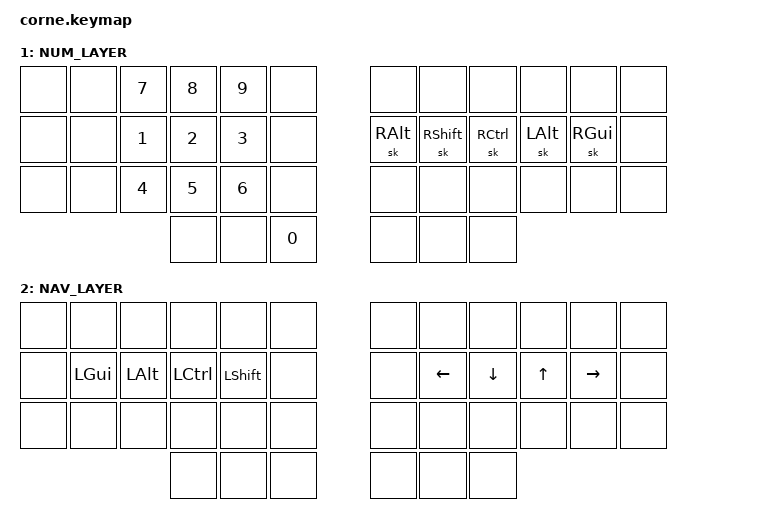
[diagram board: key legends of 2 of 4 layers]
/*
 * Copyright (c) 2020 The ZMK Contributors
 *
 * SPDX-License-Identifier: MIT
 */

#include <behaviors.dtsi>
#include <dt-bindings/zmk/keys.h>
#include <dt-bindings/zmk/bt.h>
#include <dt-bindings/zmk/outputs.h>

#include "wrappers.h"
#include "german.dtsi"

#define BASE_LAYER 0
#define NUM_LAYER 1
#define NAV_LAYER 2
#define BLE_LAYER 3

/ {

    behaviors {
        hm: homerow_mods {
            compatible = "zmk,behavior-hold-tap";
            label = "homerow mods";
            #binding-cells = <2>;
            tapping_term_ms = <110>;
            flavor = "tap-preferred";
            bindings = <&kp>, <&kp>;
        };

        mtl: mtl {
            compatible = "zmk,behavior-hold-tap";
            label = "Mod Tap Left";
            #binding-cells = <2>;
            flavor = "tap-preferred";
            tapping-term-ms = <333>;// <---[[produces mod if held longer than tapping-term-ms]]
            quick-tap-ms = <100>;
            bindings = <&kp>, <&kp>;
            hold-trigger-key-positions = <6 7 8 9 10 18 19 20 21 22 30 31 32 33 34 39 40 41>;    // <---[[right-hand keys]]
        };

        mtr: mtr {
            compatible = "zmk,behavior-hold-tap";
            label = "Mod Tap Right";
            #binding-cells = <2>;
            flavor = "tap-preferred";
            tapping-term-ms = <333>;// <---[[produces mod if held longer than tapping-term-ms]]
            quick-tap-ms = <100>;
            bindings = <&kp>, <&kp>;
            hold-trigger-key-positions = <1 2 3 4 5 13 14 15 16 17 25 26 27 28 29>;    // <---[[left-hand keys]]
        };
    };

 /* LEFT HAND SIDE POSITIONS
 *    ┌────┬────┬────┬────┬────┐
 * 00 │ 01 │ 02 │ 03 │ 04 │ 05 │ L
 *    ├────┼────┼────┼────┼────┤ E
 * 12 │ 13 │ 14 │ 15 │ 16 │ 17 │ F
 *    ├────┼────┼────┼────┼────┤ T
 * 24 │ 25 │ 26 │ 27 │ 28 │ 29 │
 *    └────┴────┴────┴────┴────┘
 */
    combos {
        compatible = "zmk,combos";

      // "<"
      combo_LESS_THAN {
            timeout-ms = <50>;
            key-positions = <1 2>;
            bindings = <&kp deLESS_THAN>;
        };

      // "("
      combo_LEFT_PARENTHESIS {
            timeout-ms = <50>;
            key-positions = <2 3>;
            bindings = <&kp deLEFT_PARENTHESIS>;
        };

      // "{"
      combo_LEFT_BRACE {
            timeout-ms = <50>;
            key-positions = <3 4>;
            bindings = <&kp deLEFT_BRACE>;
        };

      // "["
      combo_LEFT_BRACKET { // "["
            timeout-ms = <50>;
            key-positions = <4 5>;
            bindings = <&kp deLEFT_BRACKET>;
        };

      // "ESC"
      combo_esc {
            timeout-ms = <50>;
            key-positions = <15 16>;
            bindings = <&kp ESC>;
        };

      // "TAB"
      combo_tab {
            timeout-ms = <50>;
            key-positions = <14 15>;
            bindings = <&kp TAB>;
        };

      // "COPY"
      combo_COPY {
            timeout-ms = <50>;
            key-positions = <26 27>;
            bindings = <&kp LC(C)>;
        };

      // "PASTE"
      combo_PASTE {
            timeout-ms = <50>;
            key-positions = <27 28>;
            bindings = <&kp LC(V)>;
        };
 /* RIGHT HAND SIDE POSITIONS
 *   ┌────┬────┬────┬────┬────┐
 * R │ 06 │ 07 │ 08 │ 09 │ 10 │ 11
 * I ├────┼────┼────┼────┼────┤
 * G │ 18 │ 19 │ 20 │ 21 │ 22 │ 23
 * H ├────┼────┼────┼────┼────┤
 * T │ 30 │ 31 │ 32 │ 33 │ 34 │ 35
 *   └────┴────┴────┴────┴────┘
 */
        combo_enter {
            timeout-ms = <50>;
            key-positions = <19 20>;
            bindings = <&kp RET>;
        };

        combo_backspace {
            timeout-ms = <50>;
            key-positions = <20 21>;
            bindings = <&kp BSPC>;
        };

        combo_ctrl_backspace {
            timeout-ms = <50>;
            key-positions = <19 20 21>;
            bindings = <&kp LC(BSPC)>;
        };

        combo_del {
            timeout-ms = <50>;
            key-positions = <9 10>;
            bindings = <&kp DEL>;
        };
    };

    keymap {
       compatible = "zmk,keymap";
       BASE_LAYER {
          bindings = <
                  &none ___dusty_L1___                            ___dusty_R1___ &none
                  &none ___dusty_L2___                            ___dusty_R2___ &none
                  &none ___dusty_L3___                            ___dusty_R3___ &none
                  &none &lt BLE_LAYER ESC &lt NAV_LAYER SPACE    &lt NUM_LAYER E &none &none
                        >;
                };

       NUM_LAYER {
          bindings = <
  &none &none  &kp N7  &kp N8  &kp N9  &none      &none     &none       &none      &none     &none     &none
  &none &none  &kp N1  &kp N2  &kp N3  &none      &sk RALT  &sk RSHIFT  &sk RCTRL  &sk LALT  &sk RGUI  &none
  &none &none  &kp N4  &kp N5  &kp N6  &none      &none     &none       &none      &none     &none     &none
                           &none &none &kp N0      &none  &none   &none
                        >;
                };

       NAV_LAYER {
          bindings = <
  &none &none   &none   &none   &none   &none      &none     &none     &none     &none      &none      &none
  &none &kp LGUI  &kp LALT  &kp LCTRL  &kp LSHFT  &none      &none     &kp LEFT  &kp DOWN  &kp UP     &kp RIGHT  &none
  &none &none   &none   &none   &none   &none      &none     &none     &none     &none      &none      &none
                           &none &none &none      &none  &none   &none
                        >;
                };

      BLE_LAYER {
         bindings = <
                 &none ___BLE_L1___             ___NONE___ &none
                 &none ___BLE_L2___             ___NONE___ &none
                 &none ___BLE_L3___             ___NONE___ &none
                     &none &none &none     &none &none &none
                        >;
                };
        };
};
